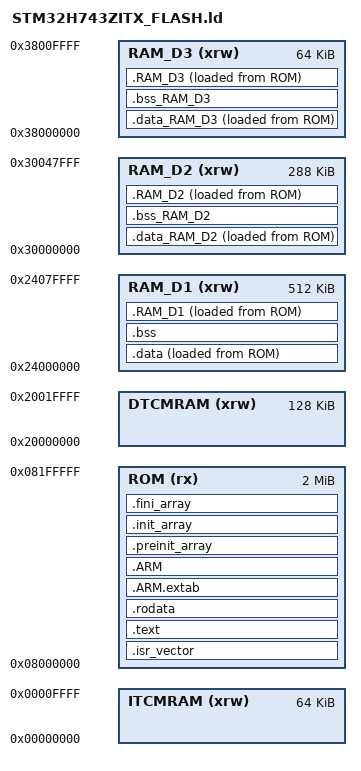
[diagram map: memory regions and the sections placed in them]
/*
******************************************************************************
**
** @file        : LinkerScript.ld
**
** @author      : Auto-generated by STM32CubeIDE
**
**  Abstract    : Linker script for NUCLEO-H743ZI Board embedding STM32H743ZITx Device from stm32h7 series
**                      2048Kbytes ROM
**                      64Kbytes ITCMRAM
**                      512Kbytes RAM
**
**                Set heap size, stack size and stack location according
**                to application requirements.
**
**                Set memory bank area and size if external memory is used
**
**  Target      : STMicroelectronics STM32
**
**  Distribution: The file is distributed as is, without any warranty
**                of any kind.
**
******************************************************************************
** @attention
**
** Copyright (c) 2022 STMicroelectronics.
** All rights reserved.
**
** This software is licensed under terms that can be found in the LICENSE file
** in the root directory of this software component.
** If no LICENSE file comes with this software, it is provided AS-IS.
**
******************************************************************************
*/

/* Entry Point */
ENTRY(Reset_Handler)

/* Highest address of the user mode stack */
_estack = ORIGIN(RAM_D1) + LENGTH(RAM_D1); /* end of "RAM_D1" Ram type memory */

_Min_Heap_Size = 0x200; /* required amount of heap */
_Min_Stack_Size = 0x400; /* required amount of stack */

/* Memories definition */
MEMORY
{
DTCMRAM (xrw)      : ORIGIN = 0x20000000, LENGTH = 128K
RAM_D1 (xrw)       : ORIGIN = 0x24000000, LENGTH = 512K
RAM_D2 (xrw)       : ORIGIN = 0x30000000, LENGTH = 288K
RAM_D3 (xrw)       : ORIGIN = 0x38000000, LENGTH = 64K
ITCMRAM (xrw)      : ORIGIN = 0x00000000, LENGTH = 64K
ROM (rx)         : ORIGIN = 0x8000000, LENGTH = 2048K
}

/* Sections */
SECTIONS
{
  /* The startup code into "ROM" Rom type memory */
  .isr_vector :
  {
    . = ALIGN(4);
    KEEP(*(.isr_vector)) /* Startup code */
    . = ALIGN(4);
  } >ROM

  /* The program code and other data into "ROM" Rom type memory */
  .text :
  {
    . = ALIGN(4);
    *(.text)           /* .text sections (code) */
    *(.text*)          /* .text* sections (code) */
    *(.glue_7)         /* glue arm to thumb code */
    *(.glue_7t)        /* glue thumb to arm code */
    *(.eh_frame)

    KEEP (*(.init))
    KEEP (*(.fini))

    . = ALIGN(4);
    _etext = .;        /* define a global symbols at end of code */
  } >ROM

  /* Constant data into "ROM" Rom type memory */
  .rodata :
  {
    . = ALIGN(4);
    *(.rodata)         /* .rodata sections (constants, strings, etc.) */
    *(.rodata*)        /* .rodata* sections (constants, strings, etc.) */
    . = ALIGN(4);
  } >ROM

  .ARM.extab (READONLY) : /* The READONLY keyword is only supported in GCC11 and later, remove it if using GCC10 or earlier. */
  {
    . = ALIGN(4);
    *(.ARM.extab* .gnu.linkonce.armextab.*)
    . = ALIGN(4);
  } >ROM

  .ARM (READONLY) : /* The READONLY keyword is only supported in GCC11 and later, remove it if using GCC10 or earlier. */
  {
    . = ALIGN(4);
    __exidx_start = .;
    *(.ARM.exidx*)
    __exidx_end = .;
    . = ALIGN(4);
  } >ROM

  .preinit_array (READONLY) : /* The READONLY keyword is only supported in GCC11 and later, remove it if using GCC10 or earlier. */
  {
    . = ALIGN(4);
    PROVIDE_HIDDEN (__preinit_array_start = .);
    KEEP (*(.preinit_array*))
    PROVIDE_HIDDEN (__preinit_array_end = .);
    . = ALIGN(4);
  } >ROM

  .init_array (READONLY) : /* The READONLY keyword is only supported in GCC11 and later, remove it if using GCC10 or earlier. */
  {
    . = ALIGN(4);
    PROVIDE_HIDDEN (__init_array_start = .);
    KEEP (*(SORT(.init_array.*)))
    KEEP (*(.init_array*))
    PROVIDE_HIDDEN (__init_array_end = .);
    . = ALIGN(4);
  } >ROM

  .fini_array (READONLY) : /* The READONLY keyword is only supported in GCC11 and later, remove it if using GCC10 or earlier. */
  {
    . = ALIGN(4);
    PROVIDE_HIDDEN (__fini_array_start = .);
    KEEP (*(SORT(.fini_array.*)))
    KEEP (*(.fini_array*))
    PROVIDE_HIDDEN (__fini_array_end = .);
    . = ALIGN(4);
  } >ROM

  /* Used by the startup to initialize data */
  _sidata = LOADADDR(.data);

  /* Initialized data sections into "RAM_D1" Ram type memory */
  .data :
  {
    . = ALIGN(4);
    _sdata = .;        /* create a global symbol at data start */
    *(.data)           /* .data sections */
    *(.data*)          /* .data* sections */
    *(.RamFunc)        /* .RamFunc sections */
    *(.RamFunc*)       /* .RamFunc* sections */

    . = ALIGN(4);
    _edata = .;        /* define a global symbol at data end */

  } >RAM_D1 AT> ROM

  /* Uninitialized data section into "RAM_D1" Ram type memory */
  . = ALIGN(4);
  .bss :
  {
    /* This is used by the startup in order to initialize the .bss section */
    _sbss = .;         /* define a global symbol at bss start */
    __bss_start__ = _sbss;
    *(.bss)
    *(.bss*)
    *(COMMON)

    . = ALIGN(4);
    _ebss = .;         /* define a global symbol at bss end */
    __bss_end__ = _ebss;
  } >RAM_D1
/* used by the startup to initialize data */
  _siRAM_D2 = LOADADDR(.data_RAM_D2);
  /* Initialized data sections goes into RAM_D2, load LMA copy after code */
  .data_RAM_D2 : 
  {
    . = ALIGN(4);
    _sRAM_D2 = .;        /* create a global symbol at data start */
    *(.data_RAM_D2)           /* .data sections */
    *(.data_RAM_D2*)          /* .data* sections */

    . = ALIGN(4);
    _eRAM_D2 = .;        /* define a global symbol at data end */
  } >RAM_D2 AT> ROM 

  /* Uninitialized data section */
  . = ALIGN(4);
  .bss_RAM_D2 :
  {
    /* This is used by the startup in order to initialize the .bss section */
    _sbss_RAM_D2 = .;         /* define a global symbol at bss start */
    __bss_start__ = _sbss_RAM_D2;
    *(.bss_RAM_D2)
    *(.bss_RAM_D2*)
    *(COMMON)

    . = ALIGN(4);
    _ebss_RAM_D2 = .;         /* define a global symbol at bss end */
    __bss_end__ = _ebss_RAM_D2;
  } >RAM_D2

/* used by the startup to initialize data */
  _siRAM_D3 = LOADADDR(.RAM_D3);

  /* Initialized data sections goes into RAM_D3, load LMA copy after code */
  .data_RAM_D3 : 
  {
    . = ALIGN(4);
    _sRAM_D3 = .;        /* create a global symbol at data start */
    *(.data_RAM_D3)           /* .data sections */
    *(.data_RAM_D3*)          /* .data* sections */

    . = ALIGN(4);
    _eRAM_D3 = .;        /* define a global symbol at data end */
  } >RAM_D3 AT> ROM 

  
  /* Uninitialized data section */
  . = ALIGN(4);
  .bss_RAM_D3 :
  {
    /* This is used by the startup in order to initialize the .bss section */
    _sbss_RAM_D3 = .;         /* define a global symbol at bss start */
    __bss_start__ = _sbss_RAM_D3;
    *(.bss_RAM_D3)
    *(.bss_RAM_D3*)
    *(COMMON)

    . = ALIGN(4);
    _ebss_RAM_D3 = .;         /* define a global symbol at bss end */
    __bss_end__ = _ebss_RAM_D3;
  } >RAM_D3


  /* Remove information from the standard libraries */
  /DISCARD/ :
  {
    libc.a ( * )
    libm.a ( * )
    libgcc.a ( * )
  }

  .ARM.attributes 0 : { *(.ARM.attributes) }
  .RAM_D1 : {*(.RAM_D1)} >RAM_D1 AT> ROM 
  .RAM_D2 : {*(.RAM_D2)} >RAM_D2 AT> ROM 
  .RAM_D3 : {*(.RAM_D3)} >RAM_D3 AT> ROM 
  
}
